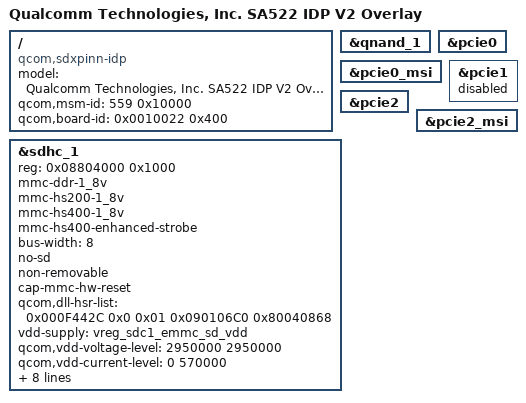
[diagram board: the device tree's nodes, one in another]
/dts-v1/;
/plugin/;

#include "sa525m-idp.dtsi"
#include "sa525m-reserved-memory-2G.dtsi"

/ {
	model = "Qualcomm Technologies, Inc. SA522 IDP V2 Overlay";
	compatible = "qcom,sdxpinn-idp",
		"qcom,sdxpinn", "qcom,idp";
	qcom,msm-id=<559 0x10000>;
	qcom,board-id = <0x0010022 0x400>;
};

&qnand_1 {
	status = "ok";
};

&pcie0 {
	status = "ok";
};

&pcie0_msi {
	status = "ok";
};

&pcie1 {
	status = "disabled";
};

&pcie2 {
	status = "ok";
};

&pcie2_msi {
	status = "ok";
};

&sdhc_1 {
	status = "ok";

	reg = <0x08804000 0x1000>;
	reg-names = "hc";

	mmc-ddr-1_8v;
	mmc-hs200-1_8v;
	mmc-hs400-1_8v;
	mmc-hs400-enhanced-strobe;

	bus-width = <8>;
	no-sd;
	non-removable;
	cap-mmc-hw-reset;

	/* DLL HSR settings. Refer go/hsr - <Target> DLL settings */
	qcom,dll-hsr-list = <0x000F442C 0x0 0x01
				0x090106C0 0x80040868>;

	vdd-supply = <&vreg_sdc1_emmc_sd_vdd>;
	qcom,vdd-voltage-level = <2950000 2950000>;
	qcom,vdd-current-level = <0 570000>;

	vdd-io-supply = <&L6B>;
	qcom,vdd-io-always-on;
	qcom,vdd-io-lpm-sup;
	qcom,vdd-io-voltage-level = <1800000 1800000>;
	qcom,vdd-io-current-level = <0 200000>;

	pinctrl-names = "default", "sleep";
	pinctrl-0 = <&sdc1_emmc_on>;
	pinctrl-1 = <&sdc1_emmc_off>;

	qcom,iommu-dma = "atomic";
};
